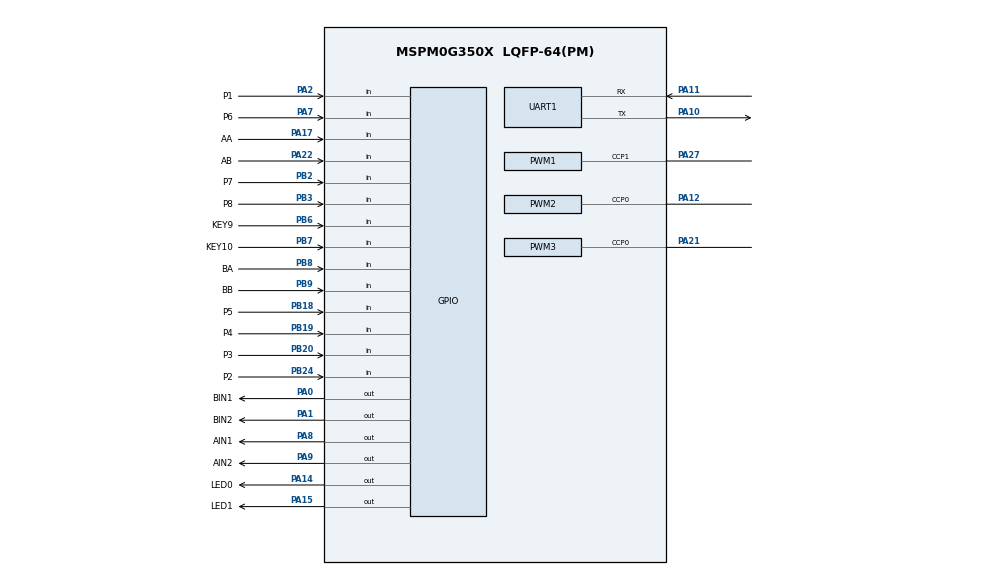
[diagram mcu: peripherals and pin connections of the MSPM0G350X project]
/**
 * @cliArgs --device "MSPM0G350X" --part "Default" --package "LQFP-64(PM)" --product "mspm0_sdk@2.10.00.04"
 * @versions {"tool":"1.26.2+4477"}
 */

/**
 * Import the modules used in this configuration.
 */
const ADC12  = scripting.addModule("/ti/driverlib/ADC12", {}, false);
const ADC121 = ADC12.addInstance();
const GPIO   = scripting.addModule("/ti/driverlib/GPIO", {}, false);
const GPIO1  = GPIO.addInstance();
const GPIO2  = GPIO.addInstance();
const GPIO3  = GPIO.addInstance();
const GPIO4  = GPIO.addInstance();
const PWM    = scripting.addModule("/ti/driverlib/PWM", {}, false);
const PWM1   = PWM.addInstance();
const PWM2   = PWM.addInstance();
const PWM3   = PWM.addInstance();
const SYSCTL = scripting.addModule("/ti/driverlib/SYSCTL");
const TIMER  = scripting.addModule("/ti/driverlib/TIMER", {}, false);
const TIMER1 = TIMER.addInstance();
const UART   = scripting.addModule("/ti/driverlib/UART", {}, false);
const UART1  = UART.addInstance();
const VREF   = scripting.addModule("/ti/driverlib/VREF");

/**
 * Write custom configuration values to the imported modules.
 */
const divider9       = system.clockTree["UDIV"];
divider9.divideValue = 2;

const multiplier2         = system.clockTree["PLL_QDIV"];
multiplier2.multiplyValue = 5;

const mux4       = system.clockTree["EXHFMUX"];
mux4.inputSelect = "EXHFMUX_XTAL";

const mux8       = system.clockTree["HSCLKMUX"];
mux8.inputSelect = "HSCLKMUX_SYSPLL0";

const pinFunction4     = system.clockTree["HFXT"];
pinFunction4.inputFreq = 40;
pinFunction4.enable    = true;

ADC121.$name                      = "xuanniu";
ADC121.adcMem0vref                = "VREF";
ADC121.adcMem0chansel             = "DL_ADC12_INPUT_CHAN_1";
ADC121.repeatMode                 = true;
ADC121.peripheral.adcPin1.$assign = "PA16";
ADC121.adcPin1Config.$name        = "ti_driverlib_gpio_GPIOPinGeneric4";

const Board = scripting.addModule("/ti/driverlib/Board", {}, false);

GPIO1.$name                         = "LED";
GPIO1.associatedPins.create(2);
GPIO1.associatedPins[0].$name       = "LED0";
GPIO1.associatedPins[0].pin.$assign = "PA14";
GPIO1.associatedPins[1].$name       = "LED1";
GPIO1.associatedPins[1].pin.$assign = "PA15";

GPIO2.$name                              = "KEY";
GPIO2.associatedPins.create(2);
GPIO2.associatedPins[0].$name            = "KEY9";
GPIO2.associatedPins[0].direction        = "INPUT";
GPIO2.associatedPins[0].internalResistor = "PULL_DOWN";
GPIO2.associatedPins[0].interruptEn      = true;
GPIO2.associatedPins[0].polarity         = "RISE";
GPIO2.associatedPins[0].pin.$assign      = "PB6";
GPIO2.associatedPins[1].$name            = "KEY10";
GPIO2.associatedPins[1].direction        = "INPUT";
GPIO2.associatedPins[1].internalResistor = "PULL_DOWN";
GPIO2.associatedPins[1].interruptEn      = true;
GPIO2.associatedPins[1].polarity         = "RISE";
GPIO2.associatedPins[1].pin.$assign      = "PB7";

GPIO3.$name                              = "DC_MOTOR";
GPIO3.associatedPins.create(8);
GPIO3.associatedPins[0].$name            = "AIN1";
GPIO3.associatedPins[0].pin.$assign      = "PA8";
GPIO3.associatedPins[1].$name            = "AIN2";
GPIO3.associatedPins[1].pin.$assign      = "PA9";
GPIO3.associatedPins[2].$name            = "AA";
GPIO3.associatedPins[2].direction        = "INPUT";
GPIO3.associatedPins[2].interruptEn      = true;
GPIO3.associatedPins[2].polarity         = "RISE";
GPIO3.associatedPins[2].internalResistor = "PULL_DOWN";
GPIO3.associatedPins[2].pin.$assign      = "PA17";
GPIO3.associatedPins[3].$name            = "AB";
GPIO3.associatedPins[3].direction        = "INPUT";
GPIO3.associatedPins[3].internalResistor = "PULL_DOWN";
GPIO3.associatedPins[3].pin.$assign      = "PA22";
GPIO3.associatedPins[4].$name            = "BIN1";
GPIO3.associatedPins[4].pin.$assign      = "PA0";
GPIO3.associatedPins[5].$name            = "BIN2";
GPIO3.associatedPins[5].pin.$assign      = "PA1";
GPIO3.associatedPins[6].$name            = "BA";
GPIO3.associatedPins[6].direction        = "INPUT";
GPIO3.associatedPins[6].interruptEn      = true;
GPIO3.associatedPins[6].internalResistor = "PULL_UP";
GPIO3.associatedPins[6].polarity         = "RISE";
GPIO3.associatedPins[6].pin.$assign      = "PB8";
GPIO3.associatedPins[7].$name            = "BB";
GPIO3.associatedPins[7].direction        = "INPUT";
GPIO3.associatedPins[7].interruptEn      = true;
GPIO3.associatedPins[7].polarity         = "RISE";
GPIO3.associatedPins[7].pin.$assign      = "PB9";

GPIO4.$name                         = "HUIDU";
GPIO4.associatedPins.create(8);
GPIO4.associatedPins[0].$name       = "P1";
GPIO4.associatedPins[0].direction   = "INPUT";
GPIO4.associatedPins[0].pin.$assign = "PA2";
GPIO4.associatedPins[1].$name       = "P2";
GPIO4.associatedPins[1].direction   = "INPUT";
GPIO4.associatedPins[1].pin.$assign = "PB24";
GPIO4.associatedPins[2].$name       = "P3";
GPIO4.associatedPins[2].direction   = "INPUT";
GPIO4.associatedPins[2].pin.$assign = "PB20";
GPIO4.associatedPins[3].$name       = "P4";
GPIO4.associatedPins[3].direction   = "INPUT";
GPIO4.associatedPins[3].pin.$assign = "PB19";
GPIO4.associatedPins[4].$name       = "P5";
GPIO4.associatedPins[4].direction   = "INPUT";
GPIO4.associatedPins[4].pin.$assign = "PB18";
GPIO4.associatedPins[5].$name       = "P6";
GPIO4.associatedPins[5].direction   = "INPUT";
GPIO4.associatedPins[5].pin.$assign = "PA7";
GPIO4.associatedPins[6].$name       = "P7";
GPIO4.associatedPins[6].direction   = "INPUT";
GPIO4.associatedPins[6].pin.$assign = "PB2";
GPIO4.associatedPins[7].$name       = "P8";
GPIO4.associatedPins[7].direction   = "INPUT";
GPIO4.associatedPins[7].pin.$assign = "PB3";

PWM1.$name                              = "SERVO";
PWM1.clockDivider                       = 8;
PWM1.clockPrescale                      = 100;
PWM1.pwmMode                            = "EDGE_ALIGN_UP";
PWM1.ccIndex                            = [1];
PWM1.timerCount                         = 2000;
PWM1.timerStartTimer                    = true;
PWM1.ccp1PinConfig.direction            = scripting.forceWrite("OUTPUT");
PWM1.ccp1PinConfig.hideOutputInversion  = scripting.forceWrite(false);
PWM1.ccp1PinConfig.onlyInternalResistor = scripting.forceWrite(false);
PWM1.ccp1PinConfig.passedPeripheralType = scripting.forceWrite("Digital");
PWM1.ccp1PinConfig.$name                = "ti_driverlib_gpio_GPIOPinGeneric7";
PWM1.peripheral.$assign                 = "TIMG7";
PWM1.peripheral.ccp1Pin.$assign         = "PA27";
PWM1.PWM_CHANNEL_1.$name                = "ti_driverlib_pwm_PWMTimerCC0";
PWM1.PWM_CHANNEL_1.dutyCycle            = 7.5;

PWM2.$name                              = "PWMA";
PWM2.ccIndex                            = [0];
PWM2.timerStartTimer                    = true;
PWM2.timerCount                         = 4000;
PWM2.pwmMode                            = "EDGE_ALIGN_UP";
PWM2.PWM_CHANNEL_0.$name                = "ti_driverlib_pwm_PWMTimerCC1";
PWM2.ccp0PinConfig.direction            = scripting.forceWrite("OUTPUT");
PWM2.ccp0PinConfig.hideOutputInversion  = scripting.forceWrite(false);
PWM2.ccp0PinConfig.onlyInternalResistor = scripting.forceWrite(false);
PWM2.ccp0PinConfig.passedPeripheralType = scripting.forceWrite("Digital");
PWM2.ccp0PinConfig.$name                = "ti_driverlib_gpio_GPIOPinGeneric6";
PWM2.peripheral.$assign                 = "TIMG0";
PWM2.peripheral.ccp0Pin.$assign         = "PA12";

PWM3.$name                              = "PWMB";
PWM3.timerCount                         = 4000;
PWM3.timerStartTimer                    = true;
PWM3.pwmMode                            = "EDGE_ALIGN_UP";
PWM3.ccIndex                            = [0];
PWM3.clockDivider                       = 2;
PWM3.PWM_CHANNEL_0.$name                = "ti_driverlib_pwm_PWMTimerCC2";
PWM3.ccp0PinConfig.direction            = scripting.forceWrite("OUTPUT");
PWM3.ccp0PinConfig.hideOutputInversion  = scripting.forceWrite(false);
PWM3.ccp0PinConfig.onlyInternalResistor = scripting.forceWrite(false);
PWM3.ccp0PinConfig.passedPeripheralType = scripting.forceWrite("Digital");
PWM3.ccp0PinConfig.$name                = "ti_driverlib_gpio_GPIOPinGeneric8";
PWM3.peripheral.ccp0Pin.$assign         = "PA21";

SYSCTL.forceDefaultClkConfig = true;
SYSCTL.clockTreeEn           = true;

TIMER1.$name              = "MOTOR_PID";
TIMER1.timerMode          = "PERIODIC_UP";
TIMER1.timerPeriod        = "10ms";
TIMER1.timerClkPrescale   = 100;
TIMER1.interrupts         = ["LOAD"];
TIMER1.peripheral.$assign = "TIMA0";

UART1.targetBaudRate                   = 115200;
UART1.enabledInterrupts                = ["RX"];
UART1.$name                            = "PRINT";
UART1.peripheral.$assign               = "UART0";
UART1.peripheral.rxPin.$assign         = "PA11";
UART1.peripheral.txPin.$assign         = "PA10";
UART1.txPinConfig.direction            = scripting.forceWrite("OUTPUT");
UART1.txPinConfig.hideOutputInversion  = scripting.forceWrite(false);
UART1.txPinConfig.onlyInternalResistor = scripting.forceWrite(false);
UART1.txPinConfig.passedPeripheralType = scripting.forceWrite("Digital");
UART1.txPinConfig.$name                = "ti_driverlib_gpio_GPIOPinGeneric2";
UART1.rxPinConfig.hideOutputInversion  = scripting.forceWrite(false);
UART1.rxPinConfig.onlyInternalResistor = scripting.forceWrite(false);
UART1.rxPinConfig.passedPeripheralType = scripting.forceWrite("Digital");
UART1.rxPinConfig.$name                = "ti_driverlib_gpio_GPIOPinGeneric3";

VREF.basicIntVolt           = "DL_VREF_BUFCONFIG_OUTPUT_2_5V";
VREF.profile                = "INT_2_5_V";
VREF.vrefPosPinConfig.$name = "ti_driverlib_gpio_GPIOPinGeneric5";

/**
 * Pinmux solution for unlocked pins/peripherals. This ensures that minor changes to the automatic solver in a future
 * version of the tool will not impact the pinmux you originally saw.  These lines can be completely deleted in order to
 * re-solve from scratch.
 */
pinFunction4.peripheral.$suggestSolution           = "SYSCTL";
pinFunction4.peripheral.hfxInPin.$suggestSolution  = "PA5";
pinFunction4.peripheral.hfxOutPin.$suggestSolution = "PA6";
ADC121.peripheral.$suggestSolution                 = "ADC1";
Board.peripheral.$suggestSolution                  = "DEBUGSS";
Board.peripheral.swclkPin.$suggestSolution         = "PA20";
Board.peripheral.swdioPin.$suggestSolution         = "PA19";
PWM3.peripheral.$suggestSolution                   = "TIMG6";
VREF.peripheral.$suggestSolution                   = "VREF";
VREF.peripheral.vrefPosPin.$suggestSolution        = "PA23";
